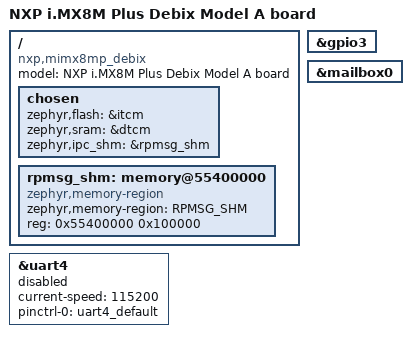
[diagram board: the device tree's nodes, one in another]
/*
 * Copyright (c) 2026, Joris Offouga
 *
 * SPDX-License-Identifier: Apache-2.0
 */

/dts-v1/;

#include <nxp/imx/nxp_imx8ml_m7.dtsi>
#include "imx8mp_debix_model_a-pinctrl.dtsi"

/ {
	model = "NXP i.MX8M Plus Debix Model A board";
	compatible = "nxp,mimx8mp_debix";

	chosen {
		/* TCM */
		zephyr,flash = &itcm;
		zephyr,sram = &dtcm;
		zephyr,ipc_shm = &rpmsg_shm;

		/*
		 * By default, Zephyr console and shell are assigned to
		 * remoteproc. To enable console and shell over UART, uncomment
		 * following lines and set the correct config in
		 * stm32mp157c_dk2_defconfig "Serial Port" section in Zephyr
		 * board documentation.
		 * zephyr,console = &uart4;
		 * zephyr,shell-uart = &uart4;
		 */
	};

	rpmsg_shm: memory@55400000 {
		compatible = "zephyr,memory-region";
		zephyr,memory-region = "RPMSG_SHM";
		reg = <0x55400000 0x100000>;
	};
};

&uart4 {
	status = "disabled";
	current-speed = <115200>;
	pinctrl-0 = <&uart4_default>;
	pinctrl-names = "default";
};

&gpio3 {
	status = "okay";
};

&mailbox0 {
	status = "okay";
};
